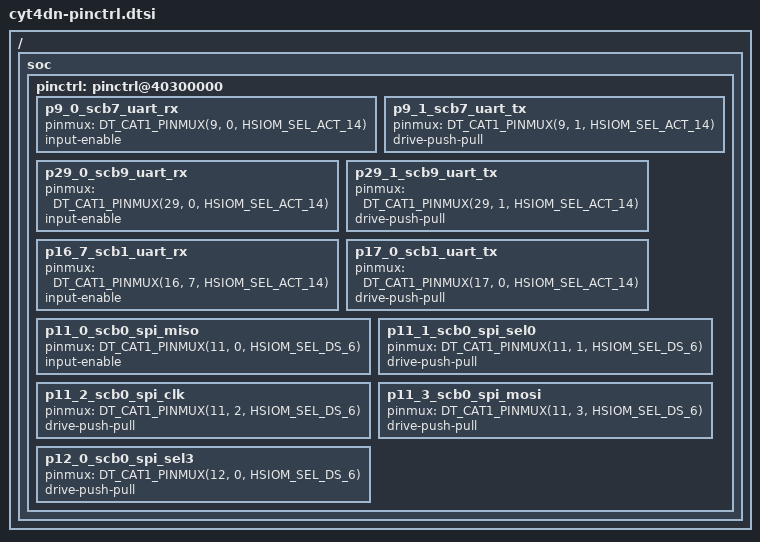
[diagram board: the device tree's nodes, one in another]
/*
 * SPDX-FileCopyrightText: Copyright (c) 2026 Linumiz
 *
 * SPDX-License-Identifier: Apache-2.0
 */

#include <zephyr/dt-bindings/gpio/gpio.h>
#include <zephyr/dt-bindings/pinctrl/ifx_cat1-pinctrl.h>
#include "cyt4dn.dtsi"

/ {
	soc {
		pinctrl: pinctrl@40300000 {
			/omit-if-no-ref/ p9_0_scb7_uart_rx: p9_0_scb7_uart_rx {
				pinmux = <DT_CAT1_PINMUX(9, 0, HSIOM_SEL_ACT_14)>;
				input-enable;
			};

			/omit-if-no-ref/ p9_1_scb7_uart_tx: p9_1_scb7_uart_tx {
				pinmux = <DT_CAT1_PINMUX(9, 1, HSIOM_SEL_ACT_14)>;
				drive-push-pull;
			};

			/omit-if-no-ref/ p29_0_scb9_uart_rx: p29_0_scb9_uart_rx {
				pinmux = <DT_CAT1_PINMUX(29, 0, HSIOM_SEL_ACT_14)>;
				input-enable;
			};

			/omit-if-no-ref/ p29_1_scb9_uart_tx: p29_1_scb9_uart_tx {
				pinmux = <DT_CAT1_PINMUX(29, 1, HSIOM_SEL_ACT_14)>;
				drive-push-pull;
			};

			/omit-if-no-ref/ p16_7_scb1_uart_rx: p16_7_scb1_uart_rx {
				pinmux = <DT_CAT1_PINMUX(16, 7, HSIOM_SEL_ACT_14)>;
				input-enable;
			};

			/omit-if-no-ref/ p17_0_scb1_uart_tx: p17_0_scb1_uart_tx {
				pinmux = <DT_CAT1_PINMUX(17, 0, HSIOM_SEL_ACT_14)>;
				drive-push-pull;
			};

			/omit-if-no-ref/ p11_0_scb0_spi_miso: p11_0_scb0_spi_miso {
				pinmux = <DT_CAT1_PINMUX(11, 0, HSIOM_SEL_DS_6)>;
				input-enable;
			};

			/omit-if-no-ref/ p11_1_scb0_spi_sel0: p11_1_scb0_spi_sel0 {
				pinmux = <DT_CAT1_PINMUX(11, 1, HSIOM_SEL_DS_6)>;
				drive-push-pull;
			};

			/omit-if-no-ref/ p11_2_scb0_spi_clk: p11_2_scb0_spi_clk {
				pinmux = <DT_CAT1_PINMUX(11, 2, HSIOM_SEL_DS_6)>;
				drive-push-pull;
			};

			/omit-if-no-ref/ p11_3_scb0_spi_mosi: p11_3_scb0_spi_mosi {
				pinmux = <DT_CAT1_PINMUX(11, 3, HSIOM_SEL_DS_6)>;
				drive-push-pull;
			};

			/omit-if-no-ref/ p12_0_scb0_spi_sel3: p12_0_scb0_spi_sel3 {
				pinmux = <DT_CAT1_PINMUX(12, 0, HSIOM_SEL_DS_6)>;
				drive-push-pull;
			};
		};
	};
};
